# SYS register map
Vendor: Texas Instruments
Peripheral module from a debugger description file (folder omap36xx).
Registers are 32-bit, read-write, reset 0x5555 unless marked. A register's access mark holds for its fields unless they carry their own. Offsets are as the file gives them; lines under a group give offsets from that group; [hi:lo] are bit positions; {n}, {i} and the like mark numbered series; 'fields as' and 'values as' point back to an identical list; <NAME> marks a mode.

## SYS
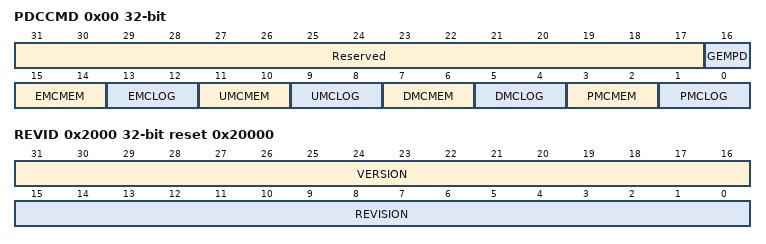
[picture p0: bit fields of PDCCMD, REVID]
0x00 PDCCMD — Power-Down Command Register
  [31:17] Reserved — Write 0s for future compatibility.Read returns 0.
  [16] GEMPD — Power-down during IDLE:GEMPD = 0: Normal operation. Do not power-down CPU or DSP megamodule when CPU is IDLE.GEMPD = 1: Sleep mode. Power-down CPU and DSP megamodule when CPU enters IDLE state
  [15:14] EMCMEM — SRAM Sleep ModesDetermines the RAM sleep modes used by the EMC for powering-down internal memories.
    0=No sleep mode supported; 1=Sleep mode 1; 2=EMCMEM_2_w (Sleep mode 2 - equivalent to sleep mode 1); 3=EMCMEM_3_w (Sleep mode 3 - equivalent to sleep mode 1)
  [13:12] EMCLOG — Logic Clock Gating Modes.Determines to what degree the EMC gates its clockinternally.
    0=No clock gating supported beyond leaf clock gating; 1=Static clock gating of unused modulesregions when DSP megamodule is active(pmc_pd_pdstat[1:0] = 00) and Static clock gating when DSP megamodule is in standby (pmc_pd_pdstat[1:0] = 11)
  [11:10] UMCMEM — SRAM Sleep ModesDetermines the RAM sleep modes used by the UMC for powering-down L2 pages.
    0=No sleep mode supported; 1=Sleep mode 1; 2=UMCMEM_2_w (Sleep mode 2 - equivalent to sleep mode 1); 3=UMCMEM_3_w (Sleep mode 3 - equivalent to sleep mode 1)
  [9:8] UMCLOG — Logic Clock Gating Modes.Determines to what degree the UMC gates its clockinternally.
    values as EMCLOG
  [7:6] DMCMEM — SRAM Sleep ModesDetermines the RAM sleep modes used by the DMC for powering-down L1D pages.
    0=No sleep mode supported; 1=Sleep mode 1; 2=DMCMEM_2_w (Sleep mode 2 - equivalent to sleep mode 1); 3=DMCMEM_3_w (Sleep mode 3 - equivalent to sleep mode 1)
  [5:4] DMCLOG — Logic Clock Gating Modes.Determines to what degree the DMC gates its clockinternally.
    0=No clock gating supported beyond leaf clock gating; 1=Static clock gating of unused modulesregions when DSP megamodule is active (pmc_pd_pdstat[1:0] = 00) and Static clock gating when DSP megamodule is in standby (pmc_pd_pdstat[1:0] = 11)
  [3:2] PMCMEM — SRAM Sleep ModesDetermines the RAM sleep modes used by the PMC for powering-down L1P pages.
    0=No sleep mode supported; 1=Sleep mode 1; 2=PMCMEM_2_w (Sleep mode 2 - equivalent to sleep mode 1); 3=PMCMEM_3_w (Sleep mode 3 - equivalent to sleep mode 1)
  [1:0] PMCLOG — Logic Clock Gating Modes.Determines to what degree the PMC gates its clockinternally.
    values as DMCLOG
0x2000 REVID ro reset 0x20000 — DSP megamodule Revision ID Register
  [31:16] VERSION — Functional implementation of DSP megamodule 0x0002 : MidGEM
  [15:0] REVISION — Physical implementation of DSP megamodule version
